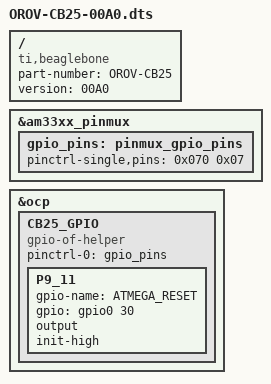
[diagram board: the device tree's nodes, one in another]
/dts-v1/;
/plugin/;

/ {
        compatible      = "ti,beaglebone", "ti,beaglebone-black";
        part-number     = "OROV-CB25";
        version         = "00A0";

        /* Pins used by this overlay */
        /* "P9.11", */               /* ATMEGA RESET */

        fragment@0 {
                target = <&am33xx_pinmux>;
                __overlay__ {

                        gpio_pins: pinmux_gpio_pins {
                                pinctrl-single,pins = <
                                        0x070 0x07              /* P9_11 GPIO0_30 | OUTPUT | Mode7 */
                                >;
                        };
                };
        };
	
        fragment@1 {
                target = <&ocp>;
                __overlay__ {
                        CB25_GPIO {
                                compatible = "gpio-of-helper";
                                status = "okay";
                                pinctrl-names = "default";
                                pinctrl-0 = <&gpio_pins>;

                                P9_11 {
                                        gpio-name = "ATMEGA_RESET";
                                        gpio = <&gpio0 30 0x00>;
                                        output;
                                        init-high;
                                };
                        };
                };
        };
};
